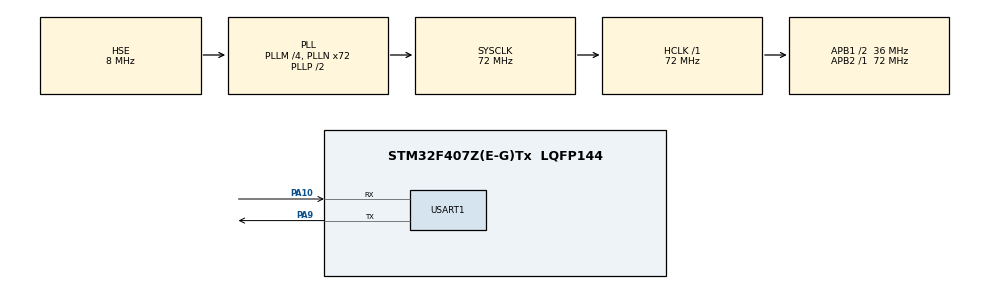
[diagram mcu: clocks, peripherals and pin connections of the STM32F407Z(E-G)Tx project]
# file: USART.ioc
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Mcu.Family=STM32F4
Mcu.Name=STM32F407Z(E-G)Tx
Mcu.Package=LQFP144
NVIC.PriorityGroup=NVIC_PRIORITYGROUP_4
NVIC.USART1_IRQn=true\:1\:0\:true\:false\:true\:true\:true
PA10.Mode=Asynchronous
PA10.Signal=USART1_RX
PA9.Mode=Asynchronous
PA9.Signal=USART1_TX
PH0-OSC_IN.Mode=HSE-External-Oscillator
PH0-OSC_IN.Signal=RCC_OSC_IN
PH1-OSC_OUT.Mode=HSE-External-Oscillator
PH1-OSC_OUT.Signal=RCC_OSC_OUT
ProjectManager.HeapSize=0x200
ProjectManager.StackSize=0x400
ProjectManager.TargetToolchain=MDK-ARM V5
RCC.48MHZClocksFreq_Value=36000000
RCC.AHBFreq_Value=72000000
RCC.APB1CLKDivider=RCC_HCLK_DIV2
RCC.APB1Freq_Value=36000000
RCC.APB1TimFreq_Value=72000000
RCC.APB2Freq_Value=72000000
RCC.APB2TimFreq_Value=72000000
RCC.CortexFreq_Value=72000000
RCC.HCLKFreq_Value=72000000
RCC.HSE_VALUE=8000000
RCC.HSI_VALUE=16000000
RCC.LSE_VALUE=32768
RCC.PLLM=4
RCC.PLLN=72
RCC.PLLSourceVirtual=RCC_PLLSOURCE_HSE
RCC.SYSCLKFreq_VALUE=72000000
RCC.SYSCLKSource=RCC_SYSCLKSOURCE_PLLCLK
RCC.VCOOutputFreq_Value=144000000
USART1.VirtualMode=VM_ASYNC
board=custom

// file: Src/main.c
/* USER CODE BEGIN Header */
/**
  ******************************************************************************
  * @file           : main.c
  * @brief          : Main program body
  ******************************************************************************
  * @attention
   USART串口通信
	 实现Printf函数功能
	 实现串口数据收发
	 使用串口：USATR1  PA9,PA10
	 芯片型号： STM32F407ZET6
  ******************************************************************************
  */
/* USER CODE END Header */

#include "main.h"
#include "usart.h"
#include "gpio.h"
#include "stm32f4xx_hal.h"
#include <string.h>

/* USER CODE BEGIN PD */
 #define RXBUFFERSIZE  256
/* USER CODE END PD */

/* USER CODE BEGIN PV */

char RxBuffer[RXBUFFERSIZE];  //接收数据
uint8_t aRxBuffer;			//接收中断缓冲
uint16_t Uart1_Rx_Cnt = 0;		//接收缓冲计数
/* USER CODE END PV */

void SystemClock_Config(void);

int main(void)
{

  /* MCU Configuration--------------------------------------------------------*/

  /* Reset of all peripherals, Initializes the Flash interface and the Systick. */
  HAL_Init();

  /* Configure the system clock */
  SystemClock_Config();

  /* Initialize all configured peripherals */
  MX_GPIO_Init();
  MX_USART1_UART_Init();
  /* USER CODE BEGIN 2 */
	HAL_UART_Receive_IT(&huart1, (uint8_t *)&aRxBuffer, 1);
  /* USER CODE END 2 */

  /* Infinite loop */
  while (1)
  {
			printf("Z小旋测试");
			HAL_Delay(1000);
		//	HAL_UART_RxCpltCallback(&huart1);
  }
}
/* USER CODE BEGIN 4 */
/**
  * @brief  Rx Transfer completed callbacks.
  * @param  huart pointer to a UART_HandleTypeDef structure that contains
  *                the configuration information for the specified UART module.
  * @retval None
  */
/* USER CODE BEGIN 4 */

/* USER CODE BEGIN 4 */

/* USER CODE BEGIN 4 */

/* USER CODE BEGIN 4 */

void HAL_UART_RxCpltCallback(UART_HandleTypeDef *huart)
{
  /* Prevent unused argument(s) compilation warning */
  UNUSED(huart);
  /* NOTE: This function Should not be modified, when the callback is needed,
           the HAL_UART_TxCpltCallback could be implemented in the user file
   */

	if(Uart1_Rx_Cnt >= 255)  //溢出判断
	{
		Uart1_Rx_Cnt = 0;
		memset(RxBuffer,0x00,sizeof(RxBuffer));
		HAL_UART_Transmit(&huart1, (uint8_t *)"数据溢出", Uart1_Rx_Cnt,0xFFFF);

	}
	else
	{
		RxBuffer[Uart1_Rx_Cnt++] = aRxBuffer;   //接收数据转存

		if((RxBuffer[Uart1_Rx_Cnt-1] == 0x0A)&&(RxBuffer[Uart1_Rx_Cnt-2] == 0x0D)) //判断结束位
		{
			HAL_UART_Transmit(&huart1, (uint8_t *)&RxBuffer, Uart1_Rx_Cnt,0xFFFF); //将收到的信息发送出去
     while(HAL_UART_GetState(&huart1) == HAL_UART_STATE_BUSY_TX)//检测UART发送结束
			Uart1_Rx_Cnt = 0;
			memset(RxBuffer,0x00,sizeof(RxBuffer)); //清空数组
		}
	}

	HAL_UART_Receive_IT(&huart1, (uint8_t *)&aRxBuffer, 1);   //再开启接收中断
}
/* USER CODE END 4 */

void SystemClock_Config(void)
{
  RCC_OscInitTypeDef RCC_OscInitStruct = {0};
  RCC_ClkInitTypeDef RCC_ClkInitStruct = {0};

  /** Configure the main internal regulator output voltage
  */
  __HAL_RCC_PWR_CLK_ENABLE();
  __HAL_PWR_VOLTAGESCALING_CONFIG(PWR_REGULATOR_VOLTAGE_SCALE1);
  /** Initializes the CPU, AHB and APB busses clocks
  */
  RCC_OscInitStruct.OscillatorType = RCC_OSCILLATORTYPE_HSE;
  RCC_OscInitStruct.HSEState = RCC_HSE_ON;
  RCC_OscInitStruct.PLL.PLLState = RCC_PLL_ON;
  RCC_OscInitStruct.PLL.PLLSource = RCC_PLLSOURCE_HSE;
  RCC_OscInitStruct.PLL.PLLM = 4;
  RCC_OscInitStruct.PLL.PLLN = 72;
  RCC_OscInitStruct.PLL.PLLP = RCC_PLLP_DIV2;
  RCC_OscInitStruct.PLL.PLLQ = 4;
  if (HAL_RCC_OscConfig(&RCC_OscInitStruct) != HAL_OK)
  {
    Error_Handler();
  }
  /** Initializes the CPU, AHB and APB busses clocks
  */
  RCC_ClkInitStruct.ClockType = RCC_CLOCKTYPE_HCLK|RCC_CLOCKTYPE_SYSCLK
                              |RCC_CLOCKTYPE_PCLK1|RCC_CLOCKTYPE_PCLK2;
  RCC_ClkInitStruct.SYSCLKSource = RCC_SYSCLKSOURCE_PLLCLK;
  RCC_ClkInitStruct.AHBCLKDivider = RCC_SYSCLK_DIV1;
  RCC_ClkInitStruct.APB1CLKDivider = RCC_HCLK_DIV2;
  RCC_ClkInitStruct.APB2CLKDivider = RCC_HCLK_DIV1;

  if (HAL_RCC_ClockConfig(&RCC_ClkInitStruct, FLASH_LATENCY_2) != HAL_OK)
  {
    Error_Handler();
  }
}

void Error_Handler(void)
{
}

/************************ (C) COPYRIGHT STMicroelectronics *****END OF FILE****/
